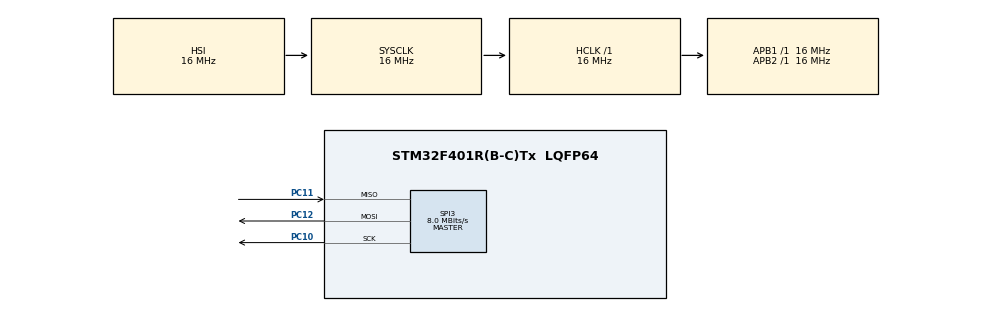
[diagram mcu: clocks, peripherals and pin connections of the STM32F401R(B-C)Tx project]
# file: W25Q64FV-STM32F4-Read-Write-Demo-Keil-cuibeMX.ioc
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Mcu.Family=STM32F4
Mcu.Name=STM32F401R(B-C)Tx
Mcu.Package=LQFP64
NVIC.PriorityGroup=NVIC_PRIORITYGROUP_4
PC10.Mode=Full_Duplex_Master
PC10.Signal=SPI3_SCK
PC11.Mode=Full_Duplex_Master
PC11.Signal=SPI3_MISO
PC12.Mode=Full_Duplex_Master
PC12.Signal=SPI3_MOSI
PC14-OSC32_IN.Mode=LSE-External-Oscillator
PC14-OSC32_IN.Signal=RCC_OSC32_IN
PC15-OSC32_OUT.Mode=LSE-External-Oscillator
PC15-OSC32_OUT.Signal=RCC_OSC32_OUT
PH0\ -\ OSC_IN.Mode=HSE-External-Oscillator
PH0\ -\ OSC_IN.Signal=RCC_OSC_IN
PH1\ -\ OSC_OUT.Mode=HSE-External-Oscillator
PH1\ -\ OSC_OUT.Signal=RCC_OSC_OUT
ProjectManager.HeapSize=0x200
ProjectManager.StackSize=0x400
ProjectManager.TargetToolchain=MDK-ARM V5.32
RCC.AHBFreq_Value=16000000
RCC.APB1Freq_Value=16000000
RCC.APB2Freq_Value=16000000
RCC.CortexFreq_Value=16000000
RCC.HSE_VALUE=25000000
RCC.HSI_VALUE=16000000
RCC.SYSCLKFreq_VALUE=16000000
RCC.VCOOutputFreq_Value=192000000
SPI3.CalculateBaudRate=8.0 MBits/s
SPI3.Direction=SPI_DIRECTION_2LINES
SPI3.Mode=SPI_MODE_MASTER
SPI3.VirtualType=VM_MASTER
board=custom

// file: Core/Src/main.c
/* USER CODE BEGIN Header */
/**
  ******************************************************************************
  * @file           : main.c
  * @brief          : Main program body
  ******************************************************************************
  * @attention
  *
  * Copyright (c) 2025 STMicroelectronics.
  * All rights reserved.
  *
  * This software is licensed under terms that can be found in the LICENSE file
  * in the root directory of this software component.
  * If no LICENSE file comes with this software, it is provided AS-IS.
  *
  ******************************************************************************
  */
/* USER CODE END Header */
#include "main.h"

/* USER CODE BEGIN Includes */
#include "W25Qxx.h"
/* USER CODE END Includes */

/* USER CODE BEGIN PD */
#define W25Q64_CS_LOW()    HAL_GPIO_WritePin(GPIOA, GPIO_PIN_4, GPIO_PIN_RESET)
#define W25Q64_CS_HIGH()   HAL_GPIO_WritePin(GPIOA, GPIO_PIN_4, GPIO_PIN_SET)
/* USER CODE END PD */

SPI_HandleTypeDef hspi3;

/* USER CODE BEGIN PV */
uint8_t cnt = 0;
uint32_t ID=0;
/* USER CODE END PV */

void SystemClock_Config(void);
static void MX_GPIO_Init(void);
static void MX_SPI3_Init(void);

int main(void)
{

  /* USER CODE BEGIN 1 */
	//W25Q_Reset();
  //ID = W25Q_ReadID();
  /* USER CODE END 1 */

  /* MCU Configuration--------------------------------------------------------*/

  /* Reset of all peripherals, Initializes the Flash interface and the Systick. */
  HAL_Init();

  /* Configure the system clock */
  SystemClock_Config();

  /* Initialize all configured peripherals */
  MX_GPIO_Init();
  MX_SPI3_Init();

  /* Infinite loop */
  while (1)
  {

    /* USER CODE BEGIN 3 */
		cnt++;
		HAL_Delay(100);
  }
  /* USER CODE END 3 */
}

void SystemClock_Config(void)
{
  RCC_OscInitTypeDef RCC_OscInitStruct = {0};
  RCC_ClkInitTypeDef RCC_ClkInitStruct = {0};

  /** Configure the main internal regulator output voltage
  */
  __HAL_RCC_PWR_CLK_ENABLE();
  __HAL_PWR_VOLTAGESCALING_CONFIG(PWR_REGULATOR_VOLTAGE_SCALE2);

  /** Initializes the RCC Oscillators according to the specified parameters
  * in the RCC_OscInitTypeDef structure.
  */
  RCC_OscInitStruct.OscillatorType = RCC_OSCILLATORTYPE_HSI;
  RCC_OscInitStruct.HSIState = RCC_HSI_ON;
  RCC_OscInitStruct.HSICalibrationValue = RCC_HSICALIBRATION_DEFAULT;
  RCC_OscInitStruct.PLL.PLLState = RCC_PLL_NONE;
  if (HAL_RCC_OscConfig(&RCC_OscInitStruct) != HAL_OK)
  {
    Error_Handler();
  }

  /** Initializes the CPU, AHB and APB buses clocks
  */
  RCC_ClkInitStruct.ClockType = RCC_CLOCKTYPE_HCLK|RCC_CLOCKTYPE_SYSCLK
                              |RCC_CLOCKTYPE_PCLK1|RCC_CLOCKTYPE_PCLK2;
  RCC_ClkInitStruct.SYSCLKSource = RCC_SYSCLKSOURCE_HSI;
  RCC_ClkInitStruct.AHBCLKDivider = RCC_SYSCLK_DIV1;
  RCC_ClkInitStruct.APB1CLKDivider = RCC_HCLK_DIV1;
  RCC_ClkInitStruct.APB2CLKDivider = RCC_HCLK_DIV1;

  if (HAL_RCC_ClockConfig(&RCC_ClkInitStruct, FLASH_LATENCY_0) != HAL_OK)
  {
    Error_Handler();
  }
}

static void MX_SPI3_Init(void)
{

  /* SPI3 parameter configuration*/
  hspi3.Instance = SPI3;
  hspi3.Init.Mode = SPI_MODE_MASTER;
  hspi3.Init.Direction = SPI_DIRECTION_2LINES;
  hspi3.Init.DataSize = SPI_DATASIZE_8BIT;
  hspi3.Init.CLKPolarity = SPI_POLARITY_LOW;
  hspi3.Init.CLKPhase = SPI_PHASE_1EDGE;
  hspi3.Init.NSS = SPI_NSS_SOFT;
  hspi3.Init.BaudRatePrescaler = SPI_BAUDRATEPRESCALER_2;
  hspi3.Init.FirstBit = SPI_FIRSTBIT_MSB;
  hspi3.Init.TIMode = SPI_TIMODE_DISABLE;
  hspi3.Init.CRCCalculation = SPI_CRCCALCULATION_DISABLE;
  hspi3.Init.CRCPolynomial = 10;
  if (HAL_SPI_Init(&hspi3) != HAL_OK)
  {
    Error_Handler();
  }

}

static void MX_GPIO_Init(void)
{

  /* GPIO Ports Clock Enable */
  __HAL_RCC_GPIOC_CLK_ENABLE();
  __HAL_RCC_GPIOH_CLK_ENABLE();

}

void Error_Handler(void)
{
  __disable_irq();
  while (1)
  {
  }
}
